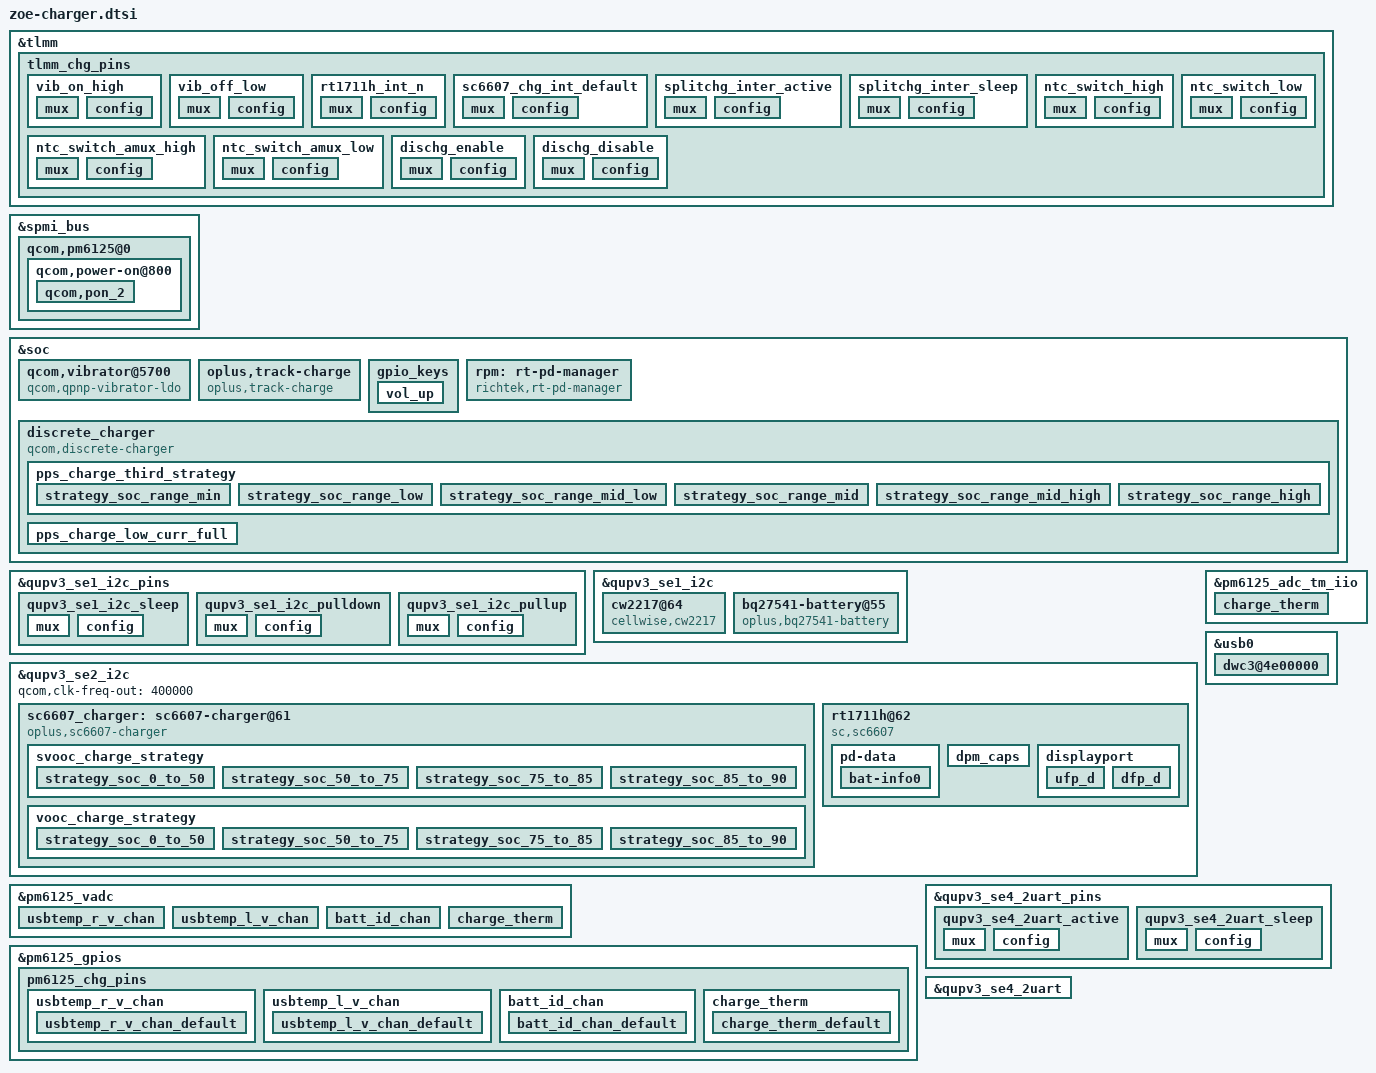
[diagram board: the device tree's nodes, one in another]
#include <dt-bindings/spmi/spmi.h>
#include <dt-bindings/iio/qcom,spmi-vadc.h>
#include <dt-bindings/iio/qti_power_supply_iio.h>
#include "zoe-thermal.dtsi"

&tlmm {
	tlmm_chg_pins: tlmm_chg_pins {
		vib_on_high: vib_on_high {
			mux {
				pins = "gpio100";
				function = "gpio";
			};

			config {
				pins = "gpio100";
				drive-strength = <2>;
				output-high;
			};
		};
		vib_off_low: vib_off_low {
			mux {
				pins = "gpio100";
				function = "gpio";
			};

			config {
				pins = "gpio100";
				drive-strength = <2>;
				output-low;
			};
		};

		rt1711h_int_n: rt1711h_int_n {
			mux {
				pins = "gpio89";
				function = "gpio";
			};

			config {
				pins = "gpio89";
				drive-strength = <2>;
				bias-disable;
			};
		};

		sc6607_chg_int_default: sc6607_chg_int_default {
			mux {
				pins = "gpio32";
				function = "gpio";
			};

			config {
				pins = "gpio32";
				drive-strength = <2>;
				bias-disable;
			};
		};
		/*split_chg*/
		splitchg_inter_active: splitchg_inter_active {
			mux {
				pins = "gpio32";
				function = "gpio";
			};
			config {
				pins = "gpio32";
				drive-strength = <2>;
				bias-pull-up;
			};
		};

		splitchg_inter_sleep: splitchg_inter_sleep {
			mux {
				pins = "gpio32";
				function = "gpio";
			};
			config {
				pins = "gpio32";
				drive-strength = <2>;
				bias-pull-up;
			};
		};

        ntc_switch_high: ntc_switch_high {
            mux {
                pins = "gpio85";
                function = "gpio";
            };

            config {
                pins = "gpio85";
                drive-strength = <2>;
                output-high;
                };
        };

        ntc_switch_low: ntc_switch_low {
            mux {
                pins = "gpio85";
                function = "gpio";
            };

            config {
                pins = "gpio85";
                drive-strength = <2>;
                output-low;
                };
        };

        ntc_switch_amux_high: ntc_switch_amux_high {
            mux {
                pins = "gpio101";
                function = "gpio";
            };

            config {
                pins = "gpio101";
                drive-strength = <2>;
                output-high;
                };
        };

        ntc_switch_amux_low: ntc_switch_amux_low {
            mux {
                pins = "gpio101";
                function = "gpio";
            };

            config {
                pins = "gpio101";
                drive-strength = <2>;
                output-low;
                };
        };

		dischg_enable: dischg_enable {
			mux {
				pins = "gpio53";
				function = "gpio";
			};

			config {
				pins = "gpio53";
				drive-strength = <2>;
				output-high;
			};
		};

		dischg_disable: dischg_disable {
			mux {
				pins = "gpio53";
				function = "gpio";
			};

			config {
				pins = "gpio53";
				drive-strength = <2>;
				output-low;
			};
		};

	};
};

&spmi_bus {
	qcom,pm6125@0 {
		qcom,power-on@800 {
			qcom,pon_2 {
				qcom,pon-type = <1>;
				qcom,pull-up = <1>;
				linux,code = <KEY_VOLUMEUP>;
			};
		};
	};
};

&soc {
	qcom,vibrator@5700 {
			compatible = "qcom,qpnp-vibrator-ldo";
			reg = <0x5700 0x100>;
			qcom,vib-ldo-volt-uv = <3000000>;
			qcom,disable-overdrive;
			qcom,vib-type = <1>;	/*0:ldo 1:gpio*/
			status = "okay";

			qcom,vibrator_switch-gpio = <&tlmm 100 0x00>;
			pinctrl-names = "vib_on_high", "vib_off_low";
			pinctrl-0 = <&vib_on_high>;
			pinctrl-1 = <&vib_off_low >;
	};

	oplus,track-charge {
		compatible = "oplus,track-charge";
		track,fast_chg_break_t_thd = <1000>;
		track,general_chg_break_t_thd = <200>;
		track,voocphy_type = <2>;
		track,wired_max_power = <33000>;
		track,wired_fast_chg_scheme = <4>;
	};

	gpio_keys {
		vol_up {
			/delete-property/ label;
			label = "volume_down";
			/delete-property/ linux,code;
			linux,code = <KEY_VOLUMEDOWN>;
		};
	};
};

&qupv3_se1_i2c_pins {
	qupv3_se1_i2c_sleep: qupv3_se1_i2c_sleep {
		mux {
			pins = "gpio4", "gpio5";
			function = "gpio";
		};

		config {
			pins = "gpio4", "gpio5";
			drive-strength = <2>;
			bias-no-pull;
			output-high;
		};
	};

	qupv3_se1_i2c_pulldown: qupv3_se1_i2c_pulldown {
		mux {
			pins = "gpio4", "gpio5";
			function = "gpio";
		};

		config {
			pins = "gpio4", "gpio5";
			drive-strength = <2>;
			bias-pull-down;
			output-low;
		};
	};

	qupv3_se1_i2c_pullup: qupv3_se1_i2c_pullup {
		mux {
			pins = "gpio4", "gpio5";
			function = "gpio";
		};

		config {
			pins = "gpio4", "gpio5";
			drive-strength = <2>;
			bias-pull-up;
			input-enable;
		};
	};
};

&qupv3_se1_i2c {
	status = "okay";
	qcom,clk-freq-out = <400000>;
	pinctrl-names = "default", "sleep", "pulldown", "pullup";
	pinctrl-0 = <&qupv3_se1_i2c_active>;
	pinctrl-1 = <&qupv3_se1_i2c_sleep>;
	pinctrl-2 = <&qupv3_se1_i2c_pulldown>;
	pinctrl-3 = <&qupv3_se1_i2c_pullup>;

    cw2217@64 {
        status = "okay";
        compatible = "cellwise,cw2217";
        reg = <0x64>;
		cw2217,battery-fcc = <5000>;
        io-channels = <&pm6125_vadc ADC5_GPIO3_100K_PU>;
        io-channel-names = "batt_id_chan";
    };

	bq27541-battery@55 {
		status = "okay";
		compatible = "oplus,bq27541-battery";
		reg = <0x55>;
		qcom,modify-soc-smooth;
		//qcom,battery-full-param;//only for wite battery full param in guage dirver probe on 7250 platform
	};

};

&soc {
	rpm: rt-pd-manager {
		compatible = "richtek,rt-pd-manager";
		#io-channel-cells = <1>;
		io-channels = <&discrete_charger PSY_IIO_PD_ACTIVE>,
			      <&discrete_charger PSY_IIO_PD_USB_SUSPEND_SUPPORTED>,
			      <&discrete_charger PSY_IIO_PD_IN_HARD_RESET>,
			      <&discrete_charger PSY_IIO_PD_CURRENT_MAX>,
			      <&discrete_charger PSY_IIO_PD_VOLTAGE_MIN>,
			      <&discrete_charger PSY_IIO_PD_VOLTAGE_MAX>,
			      <&discrete_charger PSY_IIO_USB_REAL_TYPE>,
			      <&discrete_charger PSY_IIO_PD_SDP>;
		io-channel-names = "pd_active",
				   "pd_usb_suspend_supported",
				   "pd_in_hard_reset",
				   "pd_current_max",
				   "pd_voltage_min",
				   "pd_voltage_max",
				   "real_type",
				   "pd_sdp";
	};
};

&qupv3_se2_i2c {
	status = "okay";
	qcom,clk-freq-out = <400000>;
	sc6607_charger:sc6607-charger@61 {
		status = "okay";
		compatible = "oplus,sc6607-charger";
		reg = <0x61>; /*The device operates as a slave device with address 75H*/

		qcom,chg_irq_gpio = <&tlmm 32 0x00>;
		dpdm-supply = <&usb2_phy0>;
		pinctrl-names = "default",
					"splitchg_inter_active",
					"splitchg_inter_sleep";

		pinctrl-0 = <&sc6607_chg_int_default>;
		pinctrl-1 = <&splitchg_inter_active>;
		pinctrl-2 = <&splitchg_inter_sleep>;

		sc,vsys-limit = <3400>;
		sc,vbat = <4450>;
		sc,charge-curr = <2000>;
		sc,iindpm-disable = <0>;
		sc,input-curr-limit = <500>;
		sc,ico-enable = <0>;
		sc,precharge-volt = <0>;      /* 0:2700mv , 1:3000mv */
		sc,precharge-curr = <500>;
		sc,term-en = <1>;
		sc,term-curr = <100>;     /* ma */
		sc,rechg-dis = <1>;
		sc,boost-voltage = <5000>;
		sc,boost-max-current = <1500>;
		sc,conv-ocp-dis = <0>;
		sc,tsbat-jeita-dis = <1>;
		sc,vpmid-ovp-otg-dis = <0>;
		sc,vbat-ovp-buck-dis = <0>;
		sc,ibat-ocp = <0>;    /* 0:10A , 1:12A , 2:14A , 3:16A */

		/*
		 * Charger name
		 * Main charger: primary_chg
		 * Slave charger: secondary_chg
		 */
		charger_name = "primary_chg";

		oplus,pps_dev-name = "cp-sc6607";
		oplus,pps_role_master;
		oplus,pps_ocp_max = <4800>;

		//qcom,external_gauge_support;
		//qcom,voocphy_dual_cp_support;

		qcom,slave_cp_enable_thr = <1900>;		//2000-100mA
		qcom,slave_cp_disable_thr_high = <1600>;	//1500+100mA

		qcom,voocphy_current_default = <30>;/*3000mA*/

		qcom,svooc_cool_down_current_limit = <60 20 20 24 30 34 40 44 50 54 60 60 60 60 60 60 60 60 60>;
		qcom,vooc_cool_down_current_limit = <30 20 20 24 30 30 30 30 30 30 30>;
		//qcom,abnormal_adapter_current = <122 50 50 50 40 40 30 30 20 20>;

		qcom,vooc_little_cold_full_voltage = <4460>;
		qcom,vooc_cool_full_voltage = <4460>;
		qcom,vooc_warm_full_voltage = <4130>;
		qcom,vooc_1time_full_voltage = <4510>;
		qcom,vooc_ntime_full_voltage = <4500>;
		qcom,low_curr_full_t1 = <120>;
		qcom,low_curr_full_t2 = <350>;
		qcom,low_curr_full_t3 = <430>;
		qcom,range1_low_curr_full = <650 4500
							550 4495
							450 4480
							350 4470
							250 4460>;
		qcom,range2_low_curr_full = <750 4500
							650 4495
							550 4480
							450 4470
							350 4460>;

		qcom,vooc_multistep_initial_batt_temp = <1000>;
		qcom,vooc_little_cool_temp = <160>;
		qcom,vooc_cool_temp = <120>;
		qcom,vooc_little_cold_temp = <50>;
		qcom,vooc_normal_low_temp = <250>;
		qcom,vooc_strategy_normal_current = <100>; //12.2A
		qcom,vooc_normal_to_little_cool_current = <100>;
		qcom,vooc_batt_over_high_temp = <530>;
		qcom,vooc-low-temp = <0>;
		qcom,vooc-high-temp = <500>;
		qcom,vooc-low-soc = <0>;
		qcom,vooc-high-soc = <90>;
		qcom,vooc-normal-high-temp = <430>;
		qcom,vooc-warm-allow-vol = <4000>;
		qcom,vooc-warm-allow-soc = <50>;

		qcom,vooc_strategy1_batt_high_temp0 = <400>;
		qcom,vooc_strategy1_batt_high_temp1 = <420>;
		qcom,vooc_strategy1_batt_high_temp2 = <430>;
		qcom,vooc_strategy1_batt_low_temp2 = <420>;
		qcom,vooc_strategy1_batt_low_temp1 = <410>;
		qcom,vooc_strategy1_batt_low_temp0 = <390>;

		qcom,vooc_strategy1_high_current0 = <50>;
		qcom,vooc_strategy1_high_current1 = <40>;
		qcom,vooc_strategy1_high_current2 = <20>;
		qcom,vooc_strategy1_low_current2 = <40>;
		qcom,vooc_strategy1_low_current1 = <50>;
		qcom,vooc_strategy1_low_current0 = <60>;

		qcom,vooc_strategy1_high_current0_vooc = <30>;
		qcom,vooc_strategy1_high_current1_vooc = <30>;
		qcom,vooc_strategy1_high_current2_vooc = <20>;
		qcom,vooc_strategy1_low_current2_vooc = <20>;
		qcom,vooc_strategy1_low_current1_vooc = <30>;
		qcom,vooc_strategy1_low_current0_vooc = <30>;

		qcom,voocphy_freq_mincore = <1800000>;
		qcom,voocphy_freq_midcore = <1800000>;
		qcom,voocphy_freq_maxcore = <1800000>;
		qcom,voocphy_current_change_timeout = <100>;

		qcom,voocphy_ibat_over_current = <7500>;
		qcom,voocphy_cp_max_ibus = <3500>;
		qcom,voocphy_vooc_cp_max_ibus = <3500>;

		svooc_batt_sys_curve = <0 1 0 1 0 0 0	// 4000mA
					1 1 1 1 0 0 0	// 4604mV
					0 0 1 1 0 1 0	// 2600mA
					1 1 1 1 0 0 0	// 4604mV
					0 0 0 1 0 1 1	// 1100mA
					1 1 1 1 0 0 0>;	// 4604mV

		vooc_batt_sys_curve =  <0 1 0 1 0 0 0	// 4000mA
					1 1 1 1 0 0 0	// 4604mV
					0 0 1 1 0 1 0	// 2600mA
					1 1 1 1 0 0 0	// 4604mV
					0 0 0 1 0 1 1	// 1100mA
					1 1 1 1 0 0 0>;	// 4604mV

		svooc_charge_strategy {
			strategy_soc_0_to_50 {
				strategy_temp_little_cold =	<4180 15 0 0 0
								 4460 10 1 0 0>;
				strategy_temp_cool =	<4180 20 0 0 0
								 4450 15 0 0 0
								 4460 10 1 0 0>;
				strategy_temp_little_cool =	<4460 25 0 1200 0
								 4460 23 0 0 0
								 4460 20 0 0 0
								 4490 17 0 0 0
								 4490 15 0 0 0
								 4500 10 1 0 0>;
				strategy_temp_normal_low =	<4200 30 0 1200 0 //min*60*1000/500
								 4460 25 0 1200 0 //min*60*1000/500
								 4460 23 0 0 0
								 4460 20 0 0 0
								 4490 17 0 0 0
								 4490 15 0 0 0
								 4500 10 1 0 0>;
				strategy_temp_normal_high =	<4200 30 0 1200 0 //min*60*1000/500
								 4460 25 0 1200 0 //min*60*1000/500
								 4460 23 0 0 0
								 4460 20 0 0 0
								 4490 17 0 0 0
								 4490 15 0 0 0
								 4500 10 1 0 0>;
				strategy_temp_warm = <4130 10 1 0 0>;
			};

			strategy_soc_50_to_75 {
				strategy_temp_little_cold =	<4180 15 0 0 0
								 4460 10 1 0 0>;
				strategy_temp_cool =	<4450 15 0 0 0
								 4460 10 1 0 0>;
				strategy_temp_little_cool =	<4460 23 0 0 0
								 4460 20 0 0 0
								 4490 17 0 0 0
								 4490 15 0 0 0
								 4500 10 1 0 0>;
				strategy_temp_normal_low =	<4460 23 0 0 0
								 4460 20 0 0 0
								 4490 17 0 0 0
								 4490 15 0 0 0
								 4500 10 1 0 0>;
				strategy_temp_normal_high =	<4460 23 0 0 0 //min*60*1000/500
								 4460 20 0 0 0
								 4490 17 0 0 0
								 4490 15 0 0 0
								 4500 10 1 0 0>;
				strategy_temp_warm = <4130 10 1 0 0>;
			};

			strategy_soc_75_to_85 {
				strategy_temp_little_cold =	<4460 10 1 0 0>;
				strategy_temp_cool =	<4460 10 1 0 0>;
				strategy_temp_little_cool =	<4500 10 1 0 0>;
				strategy_temp_normal_low =	<4490 15 0 0 0
								 4500 10 1 0 0>;
				strategy_temp_normal_high =	<4490 15 0 0 0
								 4500 10 1 0 0>;
				strategy_temp_warm = <4130 10 1 0 0>;
			};

			strategy_soc_85_to_90 {
				strategy_temp_little_cold =	<4460 10 1 0 0>;
				strategy_temp_cool =	<4460 10 1 0 0>;
				strategy_temp_little_cool =	<4500 10 1 0 0>;
				strategy_temp_normal_low =	<4500 10 1 0 0>;
				strategy_temp_normal_high =	<4500 10 1 0 0>;
				strategy_temp_warm = <4130 10 1 0 0>;
			};
		};

		vooc_charge_strategy {
			strategy_soc_0_to_50 {
				strategy_temp_little_cold =	<4180 30 0 0 0
								 4460 20 1 0 0>;			/*0-5C*/
				strategy_temp_cool =	<4450 30 0 0 0
								 4460 20 1 0 0>;			/*5-12C*/
				strategy_temp_little_cool =	<4490 30 0 0 0
								 4500 20 1 0 0>;			/*12-16C*/
				strategy_temp_normal_low =	<4490 30 0 0 0
								 4500 20 1 0 0>;			/*16-25C*/
				strategy_temp_normal_high =	<4490 30 0 0 0
								 4500 20 1 0 0>;			/*25C-44C*/
				strategy_temp_warm = <4130 20 1 0 0>;
			};

			strategy_soc_50_to_75 {
				strategy_temp_little_cold =	<4180 30 0 0 0
								 4460 20 1 0 0>;
				strategy_temp_cool =	<4450 30 0 0 0
								 4460 20 1 0 0>;
				strategy_temp_little_cool =	<4490 30 0 0 0
								 4500 20 1 0 0>;
				strategy_temp_normal_low =	<4490 30 0 0 0
								 4500 20 1 0 0>;
				strategy_temp_normal_high =	<4490 30 0 0 0
								 4500 20 1 0 0>;
				strategy_temp_warm = <4130 20 1 0 0>;
			};

			strategy_soc_75_to_85 {
				strategy_temp_little_cold =	<4460 20 1 0 0>;
				strategy_temp_cool =	<4460 20 1 0 0>;
				strategy_temp_little_cool =	<4500 20 1 0 0>;
				strategy_temp_normal_low =	<4490 30 0 0 0
								 4500 20 1 0 0>;
				strategy_temp_normal_high =	<4490 30 0 0 0
								 4500 20 1 0 0>;
				strategy_temp_warm = <4130 20 1 0 0>;
			};

			strategy_soc_85_to_90 {
				strategy_temp_little_cold =	<4460 20 1 0 0>;
				strategy_temp_cool =	<4460 20 1 0 0>;
				strategy_temp_little_cool =	<4500 20 1 0 0>;
				strategy_temp_normal_low =	<4500 20 1 0 0>;
				strategy_temp_normal_high =	<4500 20 1 0 0>;
				strategy_temp_warm = <4130 20 1 0 0>;
			};
		};
    };


	rt1711h@62 {
		compatible = "sc,sc6607";
		reg = <0x62>;
		status = "okay";
		tcpc-dual,supported_modes = <0>; /* 0: dfp/ufp, */
						 /* 1: dfp, 2: ufp */
		rt-tcpc,name = "type_c_port0"; /* tcpc_device's name */
		rt-tcpc,role_def = <1>; /* 0: Unknown, 1: SNK, 2: SRC */
					/* 3: DRP, 4: Try.SRC, 5: Try.SNK */
		rt-tcpc,rp_level = <0>; /* 0: Default, 1: 1.5, 2: 3.0 */
		rt-tcpc,vconn_supply  = <1>;  /* 0: Never, 1: Always, */
					      /* 2: EMarkOnly, 3: StartOnly */
		/* rt-tcpc,disable_pe; */
		rt1711pd,intr_gpio = <&tlmm 89 0x0>;
		rt1711pd,intr_gpio_num = <89>;
		rt,disable_irq_reset;
		pinctrl-names = "default";
		pinctrl-0 = <&rt1711h_int_n>;
		pd-data {
			pd,vid = <0x29cf>;
			pd,pid = <0x1711>;
			pd,source-cap-ext = <0x171129cf 0x00000000 0x00000000
					     0x00000000 0x00000000 0x02000000>;
			pd,mfrs = "RichtekTCPC";

			/*
			 *	VSAFE5V = 0, MAX_POWER = 1, CUSTOM = 2,
			 *	MAX_POWER_LV = 0x21, MAX_POWER_LVIC = 0x31
			 *	MAX_POWER_HV = 0x41, MAX_POWER_HVIC = 0x51
			 */
			pd,charging_policy= <0x31>;

			/*
			 * Fixed 5V, 500 mA <0x00019032>
			 * Fixed 5V, 1A <0x00019064>
			 * Fixed 5V, 2A <0x000190c8>
			 * Fixed 5V, 3A <0x0001912c>
			 * Fixed 9V, 500 mA <0x0002d032>
			 * Fixed 9V, 1A <0x0002d064>
			 * Fixed 9V, 2A <0x0002d0c8>
			 * Fixed 9V, 3A <0x0002d12c>
			 * Variable 5-9V, 1A <0x8642d064>
			 * Variable 5-9V, 2A <0x8642d0c8>
			 * Variable 5-9V, 3A <0x8642d12c>
			 * PPS 3V~5.9V, 3A <0xC0761E3C>
			 */
			pd,source-pdo-size = <1>;
			pd,source-pdo-data = <0x00019032>;
			pd,sink-pdo-size = <1>;
			pd,sink-pdo-data = <0x000190c8>;

			/*
			 * No DP, host + device
			 *	pd,id-vdo-size = <6>;
			 *	pd,id-vdo-data = <0xd14029cf 0x0 0x17110000
						  0x41800000 0x0 0x21800000>;
			 * With DP
			 *	pd,id-vdo-size = <6>;
			 *	pd,id-vdo-data = <0xd54029cf 0x0 0x17110000
						  0x41800000 0x0 0x21800000>;
			 */

			pd,id-vdo-size = <6>;
			pd,id-vdo-data = <0xd14029cf 0x0 0x17110000
					  0x41800000 0x0 0x21800000>;

			bat,nr = <1>;
			pd,country_nr = <0>;

			bat-info0 {
				bat,vid = <0x29cf>;
				bat,pid = <0x1711>;
				bat,mfrs = "bat1";
				bat,design_cap = <17>;
			};

			//bat-info1 {
			//	bat,vid = <0x8abc>;
			//	bat,pid = <0x5234>;
			//	bat,mfrs = "bat2";
			//	bat,design_cap = <4000>;
			//};

			//country0 {
			//	pd,country_code = <0x5457>;
			//	pd,country_len = <2>; /* max len = 26 */
			//	pd,country_data = <0xff 0xff>;
			//};

			//country1 {
			//	pd,country_code = <0x5553>;
			//	pd,country_len = <3>; /* max len = 26 */
			//	pd,country_data = <0xf1 0xf2 0xf3>;
			//};
		};
		dpm_caps {
			local_dr_power;
			local_dr_data;
			//local_ext_power;
			local_usb_comm;
			//local_usb_suspend;
			//local_high_cap;
			//local_give_back;
			local_no_suspend;
			local_vconn_supply;

			//attemp_discover_cable_dfp;
			attemp_enter_dp_mode;
			attemp_discover_cable;
			attemp_discover_id;
			attemp_discover_svid;

			/* 0: disable, 1: prefer_snk, 2: prefer_src */
			pr_check = <0>;
			//pr_reject_as_source;
			//pr_reject_as_sink;
			//pr_check_gp_source;
			//pr_check_gp_sink;

			/* 0: disable, 1: prefer_ufp, 2: prefer_dfp */
			dr_check = <0>;
			//dr_reject_as_dfp;
			//dr_reject_as_ufp;
		};
		displayport {
			/* connection type = "both", "ufp_d", "dfp_d" */
			1st_connection = "dfp_d";
			2nd_connection = "dfp_d";
			signal,dp_v13;
			//signal,dp_gen2;
			//usbr20_not_used;
			typec,receptacle;
			ufp_d {
				//pin_assignment,mode_a;
				//pin_assignment,mode_b;
				//pin_assignment,mode_c;
				//pin_assignment,mode_d;
				//pin_assignment,mode_e;
			};
			dfp_d {
				//pin_assignment,mode_a;
				//pin_assignment,mode_b;
				pin_assignment,mode_c;
				pin_assignment,mode_d;
				pin_assignment,mode_e;
				//pin_assignment,mode_f;
			};
		};
	};
};

&pm6125_vadc {
    pinctrl-0 = <&usbtemp_r_v_chan_default &usbtemp_l_v_chan_default &batt_id_chan_default &charge_therm_default>;

    usbtemp_r_v_chan {
        reg = <ADC5_GPIO1_100K_PU>;
        label = "usbtemp_r_v_chan";
        qcom,ratiometric;
        qcom,hw-settle-time = <200>;
        qcom,pre-scaling = <1 1>;
        qcom,scale-fn-type = <ADC_SCALE_HW_CALIB_DEFAULT>;
    };

    usbtemp_l_v_chan {
        reg = <ADC5_GPIO2_100K_PU>;
        label = "usbtemp_l_v_chan";
        qcom,ratiometric;
        qcom,hw-settle-time = <200>;
        qcom,pre-scaling = <1 1>;
        qcom,scale-fn-type = <ADC_SCALE_HW_CALIB_DEFAULT>;
    };

    batt_id_chan {
        reg = <ADC5_GPIO3_100K_PU>;
        label = "batt_id_chan";
        qcom,ratiometric;
        qcom,hw-settle-time = <200>;
        qcom,pre-scaling = <1 1>;
        qcom,scale-fn-type = <ADC_SCALE_HW_CALIB_DEFAULT>;
    };

    charge_therm {
        reg = <ADC5_GPIO4_100K_PU>;
        label = "charge_therm";
        qcom,ratiometric;
        qcom,hw-settle-time = <200>;
        qcom,pre-scaling = <1 1>;
        qcom,scale-fn-type = <ADC_SCALE_HW_CALIB_DEFAULT>;
    };

};

&pm6125_gpios {
	pm6125_chg_pins: pm6125_chg_pins {
        usbtemp_r_v_chan {
            usbtemp_r_v_chan_default: usbtemp_r_v_chan_default {
                pins = "gpio3";
                bias-high-impedance;
            };
        };

        usbtemp_l_v_chan {
            usbtemp_l_v_chan_default: usbtemp_l_v_chan_default {
            	pins = "gpio4";
            	bias-high-impedance;
            };
        };

        batt_id_chan {
            batt_id_chan_default: batt_id_chan_default {
                pins = "gpio6";
                bias-high-impedance;
           };
        };

        charge_therm {
            charge_therm_default: charge_therm_default {
                pins = "gpio7";
                bias-high-impedance;
            };
        };
	};
};

&pm6125_adc_tm_iio {

	charge_therm {
		reg = <2>;
		io-channels = <&pm6125_vadc ADC5_GPIO4_100K_PU>;
		qcom,ratiometric;
		qcom,hw-settle-time-us = <200>;
    };
};

&soc {
	discrete_charger: discrete_charger {
		compatible = "qcom,discrete-charger";
		status = "okay";

		oplus,chg_ops = "ext-sc6607";

		#io-channel-cells = <1>;
        io-channels = <&pm6125_vadc ADC5_GPIO1_100K_PU>,
                <&pm6125_vadc ADC5_GPIO2_100K_PU>,
                <&pm6125_vadc ADC5_GPIO3_100K_PU>;
        io-channel-names = "usbtemp_r_v_chan",
                "usbtemp_l_v_chan",
                "batt_id_chan";

        //ntc switch gpio
        qcom,ntc-switch-gpio = <&tlmm 85 0x00>;
        qcom,ntc-switch-gpio-amux = <&tlmm 101 0x00>;

		pinctrl-names = "dischg_enable", "dischg_disable",
				       "ntc_switch_high", "ntc_switch_low",
                       "ntc_switch_amux_high", "ntc_switch_amux_low";

		pinctrl-0 = <&dischg_enable>;
		pinctrl-1 = <&dischg_disable>;
		pinctrl-2 = <&ntc_switch_high>;
		pinctrl-3 = <&ntc_switch_low>;
		pinctrl-4 = <&ntc_switch_amux_high>;
		pinctrl-5 = <&ntc_switch_amux_low>;

		qcom,input_current_charger_ma = <2000>;
		qcom,pd_input_current_charger_ma = <1500>;
		qcom,qc_input_current_charger_ma = <2000>;
		qcom,input_current_usb_ma = <500>;
		qcom,input_current_cdp_ma = <1500>;
		qcom,input_current_camera_ma = <1200>;
		qcom,input_current_calling_ma = <1500>;

		qcom,led_warm_bat_decidegc = <350>;
		qcom,led_high_bat_decidegc = <370>;
		qcom,input_current_led_ma = <1200>;
		qcom,input_current_led_ma_high = <1200>;
		qcom,input_current_led_ma_warm = <1500>;
		qcom,input_current_led_ma_normal = <2000>;

		qcom,vooc_temp_bat_normal_decidegc = <350>;
		qcom,vooc_temp_bat_warm_decidegc = <370>;
		qcom,vooc_temp_bat_hot_decidegc = <440>;
		qcom,input_current_vooc_led_ma_high = <1200>;
		qcom,input_current_vooc_led_ma_warm = <1800>;
		qcom,input_current_vooc_led_ma_normal = <3600>;
		qcom,input_current_vooc_ma_normal = <3600>;
		qcom,input_current_vooc_ma_warm = <3200>;
		qcom,input_current_vooc_ma_high = <2200>;
		qcom,charger_current_vooc_ma_normal = <1800>;

		qcom,iterm_disabled = <0>;
		qcom,iterm_ma = <255>;
		qcom,recharge-mv = <100>;
		qcom,batt_capacity_mah = <5000>;/*typical capacity*/

		qcom,removed_bat_decidegc = <390>;  /*<-39C*/

		qcom,cold_bat_decidegc = <100>;  /*-10C~0C*/
		qcom,temp_cold_vfloat_mv = <4465>;
		qcom,temp_cold_fastchg_current_ma_high = <960>;
		qcom,temp_cold_fastchg_current_ma_low = <720>;
		qcom,temp_cold_fastchg_current_ma = <960>;
		qcom,pd_temp_cold_fastchg_current_ma_high = <960>;
		qcom,pd_temp_cold_fastchg_current_ma_low = <720>;
		qcom,qc_temp_cold_fastchg_current_ma_high = <960>;
		qcom,qc_temp_cold_fastchg_current_ma_low = <720>;

		qcom,little_cold_bat_decidegc = <0>;    /*0C~5C*/
		qcom,temp_little_cold_vfloat_mv = <4465>;
		qcom,temp_little_cold_fastchg_current_ma_high = <2200>;
		qcom,temp_little_cold_fastchg_current_ma_low = <2200>;
		qcom,temp_little_cold_fastchg_current_ma = <2200>;
		qcom,pd_temp_little_cold_fastchg_current_ma_high = <3300>;
		qcom,pd_temp_little_cold_fastchg_current_ma_low = <2594>;
		qcom,qc_temp_little_cold_fastchg_current_ma_high = <3300>;
		qcom,qc_temp_little_cold_fastchg_current_ma_low = <2594>;

		qcom,cool_bat_decidegc = <50>;  /*5C~12C*/
		qcom,temp_cool_vfloat_mv = <4465>;
		qcom,temp_cool_fastchg_current_ma_high = <2200>;
		qcom,temp_cool_fastchg_current_ma_low = <2200>;
		qcom,pd_temp_cool_fastchg_current_ma_high = <3300>;
		qcom,pd_temp_cool_fastchg_current_ma_low = <3300>;
		qcom,qc_temp_cool_fastchg_current_ma_high = <3300>;
		qcom,qc_temp_cool_fastchg_current_ma_low = <3300>;

		qcom,little_cool_bat_decidegc = <120>;  /*12C~16C*/
		qcom,temp_little_cool_vfloat_mv = <4465>;
		qcom,temp_little_cool_fastchg_current_ma = <2200>;
		qcom,pd_temp_little_cool_fastchg_current_ma = <3300>;
		qcom,qc_temp_little_cool_fastchg_current_ma = <3300>;

		qcom,normal_bat_decidegc = <160>;       /*16C~45C*/
		qcom,temp_normal_vfloat_mv = <4465>;
		qcom,temp_normal_fastchg_current_ma = <2200>;
		qcom,pd_temp_normal_fastchg_current_ma = <3300>;
		qcom,qc_temp_normal_fastchg_current_ma = <3300>;

		qcom,warm_bat_decidegc = <450>;         /*45C~53C*/ /*8pin Bat Vooc project need add 3 degree C*/
		qcom,temp_warm_vfloat_mv = <4130>;
		qcom,temp_warm_fastchg_current_ma = <2200>;
		qcom,pd_temp_warm_fastchg_current_ma = <1300>;
		qcom,qc_temp_warm_fastchg_current_ma = <1300>;
		qcom,temp_warm_fastchg_current_ma_led_on = <1000>;

		qcom,hot_bat_decidegc = <530>;

		qcom,non_standard_vfloat_mv = <3980>;
		qcom,non_standard_fastchg_current_ma = <512>;

		qcom,short_c_bat_cv_mv = <4330>;
		qcom,short_c_bat_vfloat_mv = <3800>;
		qcom,short_c_bat_fastchg_current_ma = <512>;

		qcom,cold_vfloat_sw_limit = <4415>;
		qcom,little_cold_vfloat_sw_limit = <4415>;
		qcom,cool_vfloat_sw_limit = <4415>;
		qcom,little_cool_vfloat_sw_limit = <4415>;
		qcom,normal_vfloat_sw_limit = <4415>;
		qcom,warm_vfloat_sw_limit = <4080>;
		qcom,non_standard_vfloat_sw_limit = <3930>;
		qcom,short_c_bat_vfloat_sw_limit = <3750>;

		qcom,max_chg_time_sec = <72000>;
		qcom,charger_hv_thr = <10000>;
		qcom,charger_recv_thr = <9800>;
		qcom,charger_lv_thr = <3400>;
		qcom,vbatt_full_thr = <4400>;
		qcom,vbatt_hv_thr = <4550>;

		qcom,vfloat_step_mv = <8>;
		qcom,cold_vfloat_over_sw_limit = <4475>;
		qcom,little_cold_vfloat_over_sw_limit = <4475>;
		qcom,cool_vfloat_over_sw_limit = <4475>;
		qcom,little_cool_vfloat_over_sw_limit = <4475>;
		qcom,normal_vfloat_over_sw_limit = <4475>;
		qcom,warm_vfloat_over_sw_limit = <4140>;
		qcom,non_standard_vfloat_over_sw_limit = <3990>;

		qcom,vbatt_power_off = <3300>;
		qcom,vbatt_soc_1 = <3410>;
		qcom,vooc_project = <5>; /*11V3A*/
		qcom,vbatt_num = <1>;
		//qcom,new_ui_warning_support;
		qcom,voocphy_support = <2>;/*AP_SINGLE_CP_VOOCPHY*/
		//qcom,chargerid_support;
		//qcom,support_subboard_ntc;
		qcom,external_gauge;
		qcom,ffc_support;
		qcom,dual_ffc;
		qcom,smart_charging_screenoff;
		qcom,vooc_show_ui_soc_decimal;
		qcom,ui_soc_decimal_speedmin = <20>;//2A
		qcom,check_batt_full_by_sw;
		qcom,chg_ctrl_by_lcd;
		qcom,chg_ctrl_by_camera;
		qcom,chg_ctrl_by_calling;

		qcom,sw_vfloat_over_protect_enable;

		qcom,normal_vterm_hw_inc = <18>;
		qcom,non_normal_vterm_hw_inc = <18>;
		qcom,usbtemp_batttemp_gap = <12>;

		qcom,ff1_normal_fastchg_ma = <1500>;
		qcom,ff1_warm_fastchg_ma = <1500>;
		qcom,ff1_exit_step_ma = <850>;
		qcom,ff1_warm_exit_step_ma = <750>;

		qcom,ffc2_normal_fastchg_ma = <800>;/*12C~35c*/
		qcom,ffc2_warm_fastchg_ma = <900>;/*35C~40c*/
		qcom,ffc2_temp_low_decidegc = <120>;
		qcom,ffc2_temp_warm_decidegc = <350>;
		qcom,ffc2_temp_high_decidegc = <400>;
		qcom,ffc2_exit_step_ma = <150>;
		qcom,ffc2_warm_exit_step_ma = <150>;

		qcom,ffc_normal_vfloat_sw_limit = <4495>;
		qcom,ffc_temp_normal_vfloat_mv = <4550>;
		qcom,ffc_normal_vfloat_over_sw_limit = <4550>;
		qcom,ffc_warm_vfloat_sw_limit = <4495>;

		qcom,ffc2_normal_vfloat_sw_limit = <4495>;
		qcom,ffc2_temp_normal_vfloat_mv = <4550>;
		qcom,ffc2_normal_vfloat_over_sw_limit = <4550>;
		qcom,ffc2_warm_vfloat_sw_limit = <4495>;

		qcom,default_iterm_ma = <255>;
		qcom,default_temp_normal_fastchg_current_ma = <2200>;
		qcom,default_normal_vfloat_sw_limit = <4410>;
		qcom,default_temp_normal_vfloat_mv = <4465>;
		qcom,default_normal_vfloat_over_sw_limit = <4475>;

		qcom,default_temp_little_cool_fastchg_current_ma = <2200>;
		qcom,default_little_cool_vfloat_sw_limit = <4410>;
		qcom,default_temp_little_cool_vfloat_mv = <4465>;
		qcom,default_little_cool_vfloat_over_sw_limit = <4475>;

		//for PD9V or QC9V
		qcom,vbatt_pdqc_to_5v_thr = <4500>;
		qcom,vbatt_pdqc_to_9v_thr = <4500>;

		//GPIO config:
		//qcom,chargerid_switch-gpio = <&tlmm 50 0x00>;
		qcom,dischg-gpio = <&tlmm 53 0x00>;

		qcom,vooc-max-input-volt-support = <11000>;     //11V
		qcom,vooc-max-input-current-support = <3000>;   //3A
		//qcom,ccdetect-gpio = <&tlmm 91 0x00>;
		qcom,use_vooc_charging_animation;
		qcom,support_usbtemp_protect_v2;
		qcom,usbtemp_batt_temp_low = <50>;
		qcom,usbtemp_batt_temp_high = <50>;
		qcom,usbtemp_ntc_temp_low = <57>;
		qcom,usbtemp_ntc_temp_high = <69>;
		qcom,usbtemp_temp_gap_low_with_batt_temp = <7>;
		qcom,usbtemp_temp_gap_high_with_batt_temp = <12>;
		qcom,usbtemp_temp_gap_low_without_batt_temp = <12>;
		qcom,usbtemp_temp_gap_high_without_batt_temp = <24>;
		qcom,usbtemp_rise_fast_temp_low = <3>;
		qcom,usbtemp_rise_fast_temp_high = <3>;
		qcom,usbtemp_rise_fast_temp_count_low = <30>;
		qcom,usbtemp_rise_fast_temp_count_high = <20>;

		qcom,usbtemp_cool_down_ntc_low = <54>;
		qcom,usbtemp_cool_down_ntc_high = <65>;
		qcom,usbtemp_cool_down_gap_low = <12>;
		qcom,usbtemp_cool_down_gap_high = <20>;
		qcom,usbtemp_cool_down_recover_ntc_low = <48>;
		qcom,usbtemp_cool_down_recover_ntc_high = <60>;
		qcom,usbtemp_cool_down_recover_gap_low = <6>;
		qcom,usbtemp_cool_down_recover_gap_high = <15>;
		qcom,support_abnormal_adapter;
		qcom,support_3p6_standard;
		support_integrated_pmic;

		//qcom,usb_btb_support;
		qcom,batt_btb_support;
		qcom,pa_thermal_support;
		//qcom,batt_thermal_support;
		qcom,bb_thermal_support;
		qcom,charger_thermal_support;
		qcom,quiet_thermal_support;
		qcom,flash_thermal_support;

		oplus,uart_tx-gpio = <&tlmm 12 0x00>;
		oplus,uart_rx-gpio = <&tlmm 13 0x00>;

		// 3rd PPS
		oplus,pps_region_list = <0x00 0x3B 0x44 0x89 0x8B>;
		oplus,pps_priority_list = <0x44>;
		oplus,pps_ops = "cp-sc6607";
		oplus,pps_support_type = <0>;
		oplus,pps_support_third = <0>;
		oplus,pps_use_cp_vbat;
		oplus,pps_warm_allow_vol = <4000>;
		oplus,pps_warm_allow_soc = <50>;
		oplus,pps_strategy_normal_current = <3000>;//6A
		oplus,pps_over_high_or_low_current = <3000>;
		oplus,pps_timeout_third = <10800>;
		oplus,pps_timeout_oplus = <7200>;
		oplus,pps_ibat_over_third = <8000>;
		oplus,pps_ibat_over_oplus = <8000>;
		oplus,pps_full_ffc_vbat = <4500>;
		oplus,pps_full_cool_sw_vbat = <4460>;
		oplus,pps_full_normal_sw_vbat = <4500>;
		oplus,pps_full_normal_hw_vbat = <4510>;
		oplus,pps_full_warm_vbat = <4130>;
		oplus,pps_full_cool_sw_vbat_third = <4460>;
		oplus,pps_full_normal_sw_vbat_third = <4500>;
		oplus,pps_full_normal_hw_vbat_third = <4510>;
		oplus,pps_r_default = <120 10 10 15 15 15 15>;
		oplus,pps_rmos_mohm = <4>;
		oplus,pps_exit_ms = <500>;
		oplus,pps_r_limit = <280 200 140 90 50>;
		oplus,pps_strategy_batt_high_temp = <385 395 420 375 385 410>;
		oplus,pps_strategy_high_current = <3000 3000 2000 3000 3000 3000>;
		oplus,pps_charge_strategy_soc = <0 15 35 50 75 85 90>;
		oplus,pps_charge_strategy_temp = <0 50 120 160 350 430 530>;
		oplus,pps_low_curr_full_strategy_temp = <120 160 350 430>;

		pps_charge_third_strategy {
			// 0 ~ 15
			strategy_soc_range_min {
				strategy_temp_little_cold =	<11000 4180 1500 0 0
								11000 4460 1000 1 0>;
				strategy_temp_cool =		<11000 4180 2000 0 0
								11000 4450 1500 0 0
								11000 4460 1000 1 0>;
				strategy_temp_little_cool =	<11000 4460 2500 0 1200
								11000 4460 2250 0 0
								11000 4460 2000 0 0
								11000 4490 1750 0 0
								11000 4490 1500 0 0
								11000 4500 1000 1 0>;
				strategy_temp_normal_low =	<11000 4200 3000 0 1200
								11000 4460 2500 0 1200
								11000 4460 2250 0 0
								11000 4460 2000 0 0
								11000 4490 1750 0 0
								11000 4490 1500 0 0
								11000 4500 1000 1 0>;
				strategy_temp_normal_high =	<11000 4200 3000 0 1200
								11000 4460 2500 0 1200
								11000 4460 2250 0 0
								11000 4460 2000 0 0
								11000 4490 1750 0 0
								11000 4490 1500 0 0
								11000 4500 1000 1 0>;
				strategy_temp_warm =		<11000 4130 1000 1 0>;
			};
			// 15 ~ 35
			strategy_soc_range_low {
				strategy_temp_little_cold =	<11000 4180 1500 0 0
								11000 4460 1000 1 0>;
				strategy_temp_cool =		<11000 4180 2000 0 0
								11000 4450 1500 0 0
								11000 4460 1000 1 0>;
				strategy_temp_little_cool =	<11000 4460 2500 0 1200
								11000 4460 2250 0 0
								11000 4460 2000 0 0
								11000 4490 1750 0 0
								11000 4490 1500 0 0
								11000 4500 1000 1 0>;
				strategy_temp_normal_low =	<11000 4200 3000 0 1200
								11000 4460 2500 0 1200
								11000 4460 2250 0 0
								11000 4460 2000 0 0
								11000 4490 1750 0 0
								11000 4490 1500 0 0
								11000 4500 1000 1 0>;
				strategy_temp_normal_high =	<11000 4200 3000 0 1200
								11000 4460 2500 0 1200
								11000 4460 2250 0 0
								11000 4460 2000 0 0
								11000 4490 1750 0 0
								11000 4490 1500 0 0
								11000 4500 1000 1 0>;
				strategy_temp_warm =		<11000 4130 1000 1 0>;
			};
			// 35 ~ 50
			strategy_soc_range_mid_low {
				strategy_temp_little_cold =	<11000 4180 1500 0 0
								11000 4460 1000 1 0>;
				strategy_temp_cool =		<11000 4180 2000 0 0
								11000 4450 1500 0 0
								11000 4460 1000 1 0>;
				strategy_temp_little_cool =	<11000 4460 2500 0 1200
								11000 4460 2250 0 0
								11000 4460 2000 0 0
								11000 4490 1750 0 0
								11000 4490 1500 0 0
								11000 4500 1000 1 0>;
				strategy_temp_normal_low =	<11000 4200 3000 0 1200
								11000 4460 2500 0 1200
								11000 4460 2250 0 0
								11000 4460 2000 0 0
								11000 4490 1750 0 0
								11000 4490 1500 0 0
								11000 4500 1000 1 0>;
				strategy_temp_normal_high =	<11000 4200 3000 0 1200
								11000 4460 2500 0 1200
								11000 4460 2250 0 0
								11000 4460 2000 0 0
								11000 4490 1750 0 0
								11000 4490 1500 0 0
								11000 4500 1000 1 0>;
				strategy_temp_warm =		<11000 4130 1000 1 0>;
			};
			// 50 ~ 75
			strategy_soc_range_mid {
				strategy_temp_little_cold =	<11000 4180 1500 0 0
								11000 4460 1000 1 0>;
				strategy_temp_cool =		<11000 4450 1500 0 0
								11000 4460 1000 1 0>;
				strategy_temp_little_cool =	<11000 4460 2250 0 0
								11000 4460 2000 0 0
								11000 4490 1750 0 0
								11000 4490 1500 0 0
								11000 4500 1000 1 0>;
				strategy_temp_normal_low =	<11000 4460 2250 0 0
								11000 4460 2000 0 0
								11000 4490 1750 0 0
								11000 4490 1500 0 0
								11000 4500 1000 1 0>;
				strategy_temp_normal_high =	<11000 4460 2250 0 0
								11000 4460 2000 0 0
								11000 4490 1750 0 0
								11000 4490 1500 0 0
								11000 4500 1000 1 0>;
				strategy_temp_warm =		<11000 4130 1000 1 0>;
			};
			// 75 ~ 85
			strategy_soc_range_mid_high {
				strategy_temp_little_cold =	<11000 4460 1000 1 0>;
				strategy_temp_cool =		<11000 4460 1000 1 0>;
				strategy_temp_little_cool =	<11000 4500 1000 1 0>;
				strategy_temp_normal_low =	<11000 4490 1500 0 0
									11000 4500 1000 1 0>;
				strategy_temp_normal_high =	<11000 4490 1500 0 0
									11000 4500 1000 1 0>;
				strategy_temp_warm =		<11000 4130 1000 1 0>;
			};
			// 85 ~ 90
			strategy_soc_range_high {
				strategy_temp_little_cold =	<11000 4460 1000 1 0>;
				strategy_temp_cool =		<11000 4460 1000 1 0>;
				strategy_temp_little_cool =	<11000 4500 1000 1 0>;
				strategy_temp_normal_low =	<11000 4490 1500 0 0
									11000 4500 1000 1 0>;
				strategy_temp_normal_high =	<11000 4490 1500 0 0
									11000 4500 1000 1 0>;
				strategy_temp_warm =		<11000 4130 1000 1 0>;
			};
		};

		pps_charge_low_curr_full {
			strategy_temp_little_cool = 	<650 4500 0
							550 4495 0
							450 4480 0
							350 4470 0
							250 4460 1>;
			strategy_temp_normal_low =	<650 4500 0
							550 4495 0
							450 4480 0
							350 4470 0
							250 4460 1>;
			strategy_temp_normal_high = 	<750 4500 0
							650 4495 0
							550 4480 0
							450 4470 0
							350 4460 1>;
		};
	};
};

&usb0 {
	dpdm-supply = <&usb2_phy0>;
	extcon = <&rpm>;
	#io-channel-cells = <1>;
	io-channels= <&discrete_charger PSY_IIO_USB_REAL_TYPE>;
	io-channel-names = "chg_type";
	dwc3@4e00000 {
		usb-phy = <&usb2_phy0>, <&usb_nop_phy>;
		maximum-speed = "high-speed";
		dr_mode = "otg";
	};
};

&qupv3_se4_2uart_pins{
	qupv3_se4_2uart_active: qupv3_se4_2uart_active {
		mux {
			pins = "gpio12", "gpio13";
			function = "qup4";
		};

		config {
			pins = "gpio12", "gpio13";
			drive-strength = <2>;
			bias-disable;
		};
	};

	qupv3_se4_2uart_sleep: qupv3_se4_2uart_sleep {
		mux {
			pins = "gpio12", "gpio13";
			function = "gpio";
		};

		config {
			pins = "gpio12", "gpio13";
			drive-strength = <2>;
			bias-pull-down;
			input-enable;
		};
	};
};

&qupv3_se4_2uart {
	pinctrl-names = "default", "sleep";
	pinctrl-0 = <&qupv3_se4_2uart_active>;
	pinctrl-1 = <&qupv3_se4_2uart_sleep>;
	status = "ok";
};
